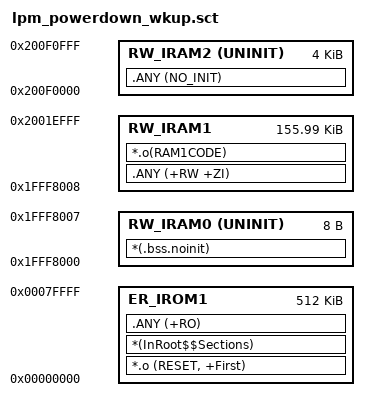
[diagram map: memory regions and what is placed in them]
; *************************************************************
; *** Scatter-Loading Description File generated by uVision ***
; *************************************************************

LR_IROM1 0x00000000 0x00080000  {    ; load region size_region
  ER_IROM1 0x00000000 0x00080000  {  ; load address = execution address
   *.o (RESET, +First)
   *(InRoot$$Sections)
   .ANY (+RO)
  }
  RW_IRAM0 0x1FFF8000 UNINIT 0x00000008  {  ; RW data
        *(.bss.noinit)
    }
  RW_IRAM1 0x1FFF8008 0x00026FF8  {  ; RW data
  
   .ANY (+RW +ZI)
    *.o(RAM1CODE)
  }
   RW_IRAM2 0x200F0000 UNINIT 0x00001000  {  ; RW data
    .ANY (NO_INIT)
  }
}

